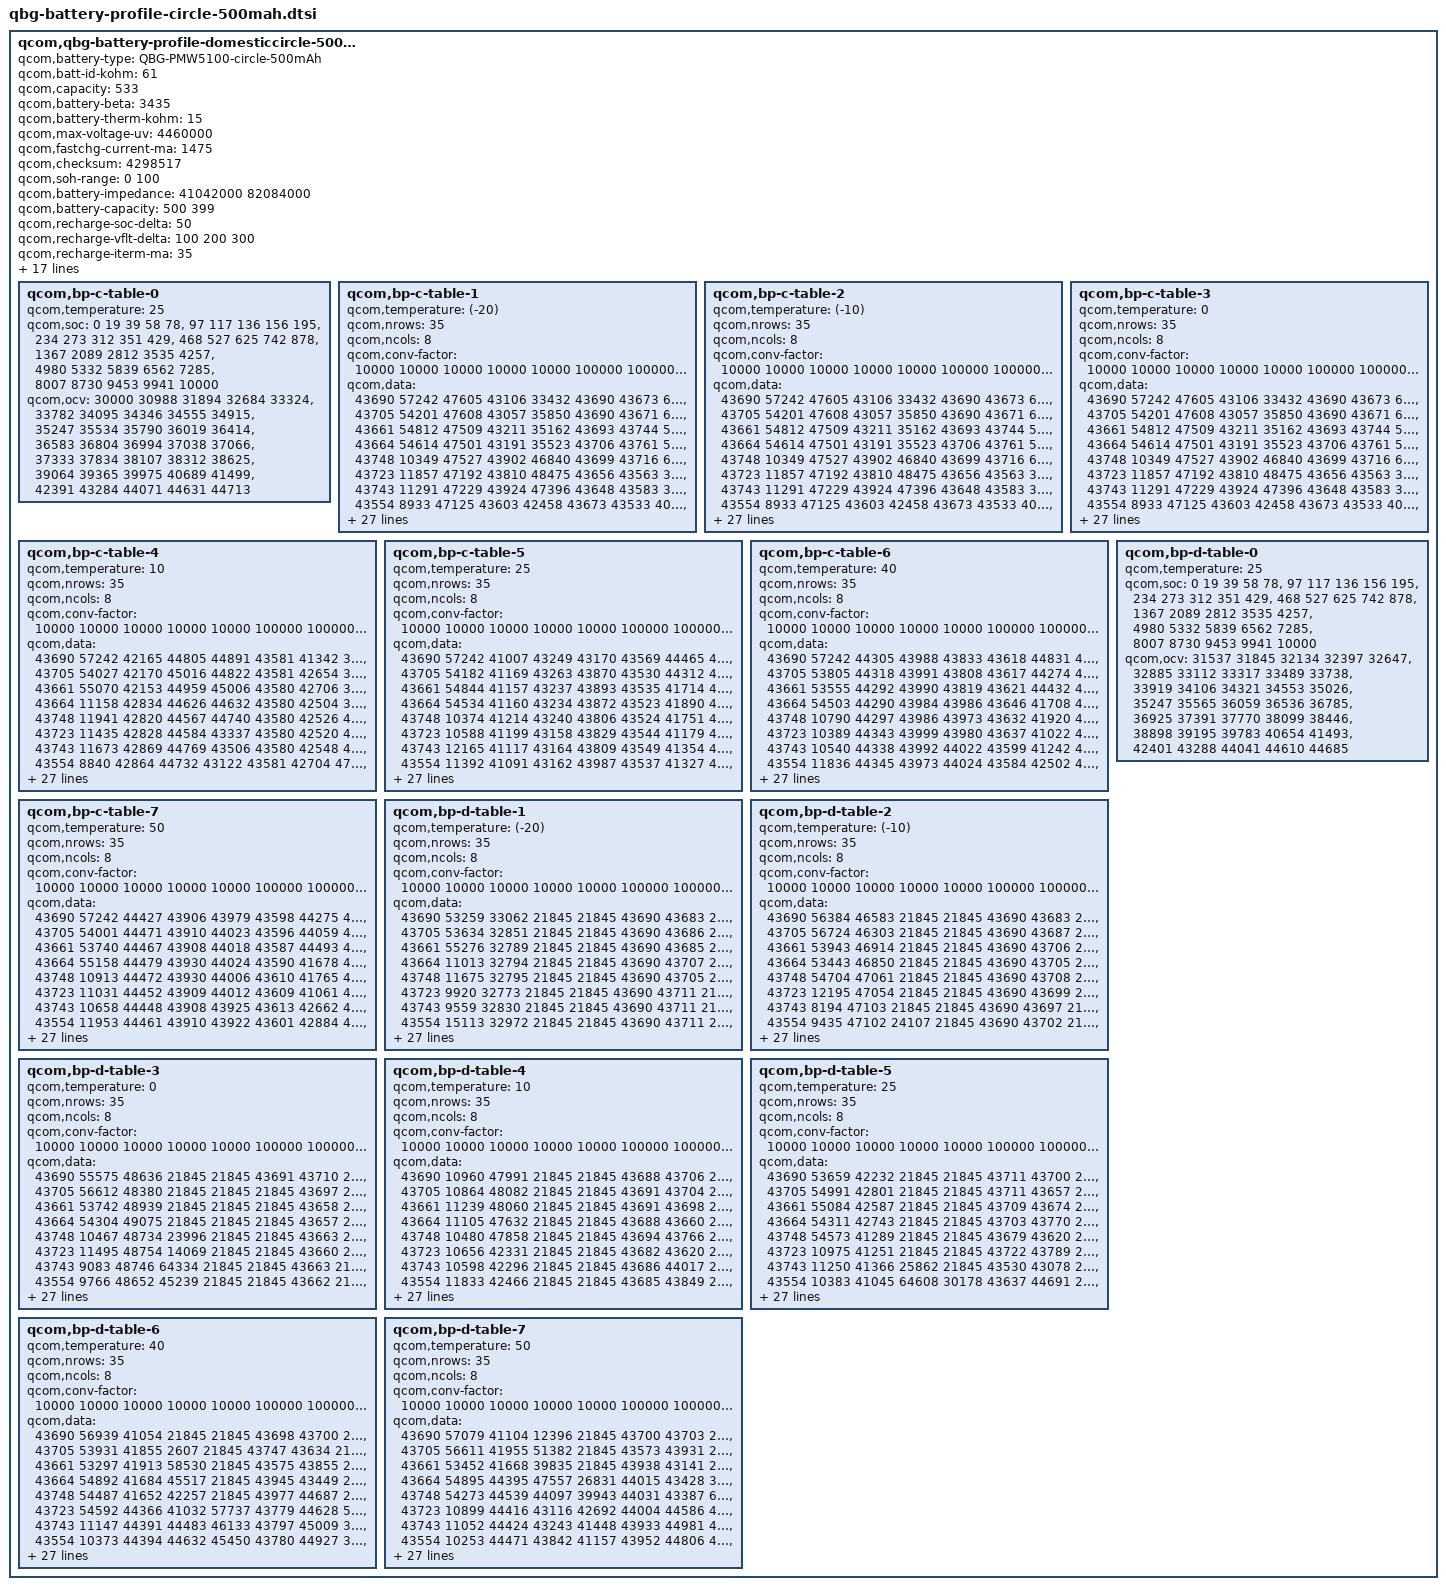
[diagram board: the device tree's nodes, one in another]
qcom,qbg-battery-profile-domesticcircle-500mAh {
	qcom,battery-type = "QBG-PMW5100-circle-500mAh";
	qcom,batt-id-kohm = <61>;
	qcom,capacity = <533>;
	qcom,battery-beta = <3435>;
	qcom,battery-therm-kohm = <15>;
	qcom,max-voltage-uv = <4460000>;
	qcom,fastchg-current-ma = <1475>;
	qcom,checksum = <4298517>; /*@5, 0.005V, 7% */
	qcom,soh-range = <0 100>;
	/* Nominal_Impedance in 10nohm @ SOC 50% 25C* 0:fresh cell,  1: aged cell */
	qcom,battery-impedance = <41042000 82084000>;
	/* Nominal_Capacity in mAh. 0: fresh cell,  1:aged cell */
	qcom,battery-capacity = <500 399>;
	/* SOC delta (in percent) dropped from EOC SOC to enable recharge */
	qcom,recharge-soc-delta =<50>;
	/* vfloat delta (in mV) dropped from regular vfloat in recharge */
	qcom,recharge-vflt-delta =<100 200 300>;
	/* Termination current (in mA) in recharge */
	qcom,recharge-iterm-ma = <35>;
	qcom,batt-temp-coeffs = <0 20 70 170 390 410 420 440 530>;
	qcom,batt-current-coeffs = <0 75000 225000 475000 1475000 1275000 775000 375000 225000>;
	qcom,batt-max-mv-coeffs = <4130000 4460000>;
	qcom,chg-limit-current-default = <100000 150000>;

	qcom,jeita-fcc-ranges = <0 170 475000
				171 440 1475000
				441 530 225000>;

	 qcom,jeita-fv-ranges = <0 170 4460000
				171 440 4460000
				441 530 4130000>;

	qcom,step-chg-ranges = <3400000 4250000 1475000
				4250001 4350000 975000
				4350001 4460000 575000>;

	/* COOL = 15 DegC, WARM = 70 DegC */
	qcom,jeita-soft-thresholds = <0x30DD 0x7BC>;
	/* COLD = 0 DegC, HOT = 80 DegC */
	qcom,jeita-hard-thresholds = <0x3733 0x5ed>;
	/* COOL = 18 DegC, WARM = 39 DegC*/
	qcom,jeita-soft-hys-thresholds = <0x256e 0x161b>;
	qcom,jeita-soft-fcc-ua = <100000 1475000>;
	qcom,jeita-soft-fv-uv = <4130000 4460000>;

	qcom,bp-c-table-0 {
		qcom,temperature = <25>;
		qcom,soc = <    0    19    39    58    78>,
			<   97   117   136   156   195>,
			<  234   273   312   351   429>,
			<  468   527   625   742   878>,
			< 1367  2089  2812  3535  4257>,
			< 4980  5332  5839  6562  7285>,
			< 8007  8730  9453  9941 10000>;
		qcom,ocv = <30000 30988 31894 32684 33324>,
			<33782 34095 34346 34555 34915>,
			<35247 35534 35790 36019 36414>,
			<36583 36804 36994 37038 37066>,
			<37333 37834 38107 38312 38625>,
			<39064 39365 39975 40689 41499>,
			<42391 43284 44071 44631 44713>;
	};

	qcom,bp-c-table-1 {
		qcom,temperature = <(-20)>;
		qcom,nrows = <35>;
		qcom,ncols = <8>;
		qcom,conv-factor = <10000 10000 10000 10000 10000 100000 100000 10000>;
		qcom,data = <43690 57242 47605 43106 33432 43690 43673 63810>,
			<43705 54201 47608 43057 35850 43690 43671 64309>,
			<43661 54812 47509 43211 35162 43693 43744 58558>,
			<43664 54614 47501 43191 35523 43706 43761 58162>,
			<43748 10349 47527 43902 46840 43699 43716 61142>,
			<43723 11857 47192 43810 48475 43656 43563 38334>,
			<43743 11291 47229 43924 47396 43648 43583 37659>,
			<43554  8933 47125 43603 42458 43673 43533 40457>,
			<43574  9059 47104 43543 41335 43665 43548 39573>,
			<43625  9889 47160 43718 44508 43745 43619 32799>,
			<43584 10222 47161 43768 44141 43763 43622 33584>,
			<43963  9355 47152 43758 44241 43727 43617 33726>,
			<43922  9330 47159 43677 44264 43740 43616 33328>,
			<44021  9507 47314 43651 44205 43581 43628 33445>,
			<43783 15092 47249 43699 44925 43621 43624 36332>,
			<43902 14886 47333 43709 44915 43637 43624 36256>,
			<43173 14879 47308 43711 44917 43588 43624 35954>,
			<43227 14960 47115 43697 44890 43633 43622 35856>,
			<43084 15278 47308 43657 44205 43523 43632 35949>,
			<43460 15339 47344 43656 44223 43525 43595 36050>,
			<45053 14384 47328 45051 43098 43522 41439 36250>,
			<41603 16085 47271 44806 44750 43547 42554 36330>,
			<41046 16379 47958 44221 44977 43547 42506 36332>,
			<42853 15525 47946 44286 44929 43524 42645 35940>,
			<47627 15744 47889 44224 45015 43526 41826 35939>,
			<47582 12842 47905 44250 44412 43525 42636 33534>,
			<48766 13178 47919 44281 44093 43524 42542 35952>,
			<48229 14057 48068 44165 43457 43626 41041 35230>,
			<45832 13385 48075 44283 43374 43527 41938 35310>,
			<46815  2930 47700 44038 44691 43534 41546 36492>,
			<46573  3971 47688 44119 44623 43534 44290 36609>,
			<34992   560 48008 44317 44337 43529 44822 33068>,
			<36423   284 48124 44417 48085 43534 43306 37331>,
			<35967  1894 47874 43848 47516 43712 44004 38047>,
			<36282  1208 47977 43671 47959 43760 43632 38457>;
	};

	qcom,bp-c-table-2 {
		qcom,temperature = <(-10)>;
		qcom,nrows = <35>;
		qcom,ncols = <8>;
		qcom,conv-factor = <10000 10000 10000 10000 10000 100000 100000 10000>;
		qcom,data = <43690 57242 47605 43106 33432 43690 43673 63810>,
			<43705 54201 47608 43057 35850 43690 43671 64309>,
			<43661 54812 47509 43211 35162 43693 43744 58558>,
			<43664 54614 47501 43191 35523 43706 43761 58162>,
			<43748 10349 47527 43902 46840 43699 43716 61142>,
			<43723 11857 47192 43810 48475 43656 43563 38334>,
			<43743 11291 47229 43924 47396 43648 43583 37659>,
			<43554  8933 47125 43603 42458 43673 43533 40457>,
			<43574  9059 47104 43543 41335 43665 43548 39573>,
			<43625  9889 47160 43718 44508 43745 43619 32799>,
			<43584 10222 47161 43768 44141 43763 43622 33584>,
			<43963  9355 47152 43758 44241 43727 43617 33726>,
			<43922  9330 47159 43677 44264 43740 43616 33328>,
			<44021  9507 47314 43651 44205 43581 43628 33445>,
			<43783 15092 47249 43699 44925 43621 43624 36332>,
			<43902 14886 47333 43709 44915 43637 43624 36256>,
			<43173 14879 47308 43711 44917 43588 43624 35954>,
			<43227 14960 47115 43697 44890 43633 43622 35856>,
			<43084 15278 47308 43657 44205 43523 43632 35949>,
			<43460 15339 47344 43656 44223 43525 43595 36050>,
			<45053 14384 47328 45051 43098 43522 41439 36250>,
			<41603 16085 47271 44806 44750 43547 42554 36330>,
			<41046 16379 47958 44221 44977 43547 42506 36332>,
			<42853 15525 47946 44286 44929 43524 42645 35940>,
			<47627 15744 47889 44224 45015 43526 41826 35939>,
			<47582 12842 47905 44250 44412 43525 42636 33534>,
			<48766 13178 47919 44281 44093 43524 42542 35952>,
			<48229 14057 48068 44165 43457 43626 41041 35230>,
			<45832 13385 48075 44283 43374 43527 41938 35310>,
			<46815  2930 47700 44038 44691 43534 41546 36492>,
			<46573  3971 47688 44119 44623 43534 44290 36609>,
			<34992   560 48008 44317 44337 43529 44822 33068>,
			<36423   284 48124 44417 48085 43534 43306 37331>,
			<35967  1894 47874 43848 47516 43712 44004 38047>,
			<36282  1208 47977 43671 47959 43760 43632 38457>;
	};

	qcom,bp-c-table-3 {
		qcom,temperature = <0>;
		qcom,nrows = <35>;
		qcom,ncols = <8>;
		qcom,conv-factor = <10000 10000 10000 10000 10000 100000 100000 10000>;
		qcom,data = <43690 57242 47605 43106 33432 43690 43673 63810>,
			<43705 54201 47608 43057 35850 43690 43671 64309>,
			<43661 54812 47509 43211 35162 43693 43744 58558>,
			<43664 54614 47501 43191 35523 43706 43761 58162>,
			<43748 10349 47527 43902 46840 43699 43716 61142>,
			<43723 11857 47192 43810 48475 43656 43563 38334>,
			<43743 11291 47229 43924 47396 43648 43583 37659>,
			<43554  8933 47125 43603 42458 43673 43533 40457>,
			<43574  9059 47104 43543 41335 43665 43548 39573>,
			<43625  9889 47160 43718 44508 43745 43619 32799>,
			<43584 10222 47161 43768 44141 43763 43622 33584>,
			<43963  9355 47152 43758 44241 43727 43617 33726>,
			<43922  9330 47159 43677 44264 43740 43616 33328>,
			<44021  9507 47314 43651 44205 43581 43628 33445>,
			<43783 15092 47249 43699 44925 43621 43624 36332>,
			<43902 14886 47333 43709 44915 43637 43624 36256>,
			<43173 14879 47308 43711 44917 43588 43624 35954>,
			<43227 14960 47115 43697 44890 43633 43622 35856>,
			<43084 15278 47308 43657 44205 43523 43632 35949>,
			<43460 15339 47344 43656 44223 43525 43595 36050>,
			<45053 14384 47328 45051 43098 43522 41439 36250>,
			<41603 16085 47271 44806 44750 43547 42554 36330>,
			<41046 16379 47958 44221 44977 43547 42506 36332>,
			<42853 15525 47946 44286 44929 43524 42645 35940>,
			<47627 15744 47889 44224 45015 43526 41826 35939>,
			<47582 12842 47905 44250 44412 43525 42636 33534>,
			<48766 13178 47919 44281 44093 43524 42542 35952>,
			<48229 14057 48068 44165 43457 43626 41041 35230>,
			<45832 13385 48075 44283 43374 43527 41938 35310>,
			<46815  2930 47700 44038 44691 43534 41546 36492>,
			<46573  3971 47688 44119 44623 43534 44290 36609>,
			<34992   560 48008 44317 44337 43529 44822 33068>,
			<36423   284 48124 44417 48085 43534 43306 37331>,
			<35967  1894 47874 43848 47516 43712 44004 38047>,
			<36282  1208 47977 43671 47959 43760 43632 38457>;
	};

	qcom,bp-c-table-4 {
		qcom,temperature = <10>;
		qcom,nrows = <35>;
		qcom,ncols = <8>;
		qcom,conv-factor = <10000 10000 10000 10000 10000 100000 100000 10000>;
		qcom,data = <43690 57242 42165 44805 44891 43581 41342 35171>,
			<43705 54027 42170 45016 44822 43581 42654 34932>,
			<43661 55070 42153 44959 45006 43580 42706 35663>,
			<43664 11158 42834 44626 44632 43580 42504 35401>,
			<43748 11941 42820 44567 44740 43580 42526 46410>,
			<43723 11435 42828 44584 43337 43580 42520 46155>,
			<43743 11673 42869 44769 43506 43580 42548 46916>,
			<43554  8840 42864 44732 43122 43581 42704 47015>,
			<43574  8776 42879 43342 43200 43581 42720 46831>,
			<43625  8335 42855 43301 43847 43571 41319 45490>,
			<43584  8702 42849 43502 43903 43574 41093 45259>,
			<43963  9981 42855 43438 43885 43573 44296 45940>,
			<43922 10134 42851 43085 43882 43529 44045 45864>,
			<44021  9377 42783 43135 43792 43523 44078 46056>,
			<43783  9672 42810 43117 43782 43525 44059 45694>,
			<43902  9560 42963 43115 43838 43546 44468 45620>,
			<43173 15094 42974 43028 43823 43544 44524 45793>,
			<43227 14901 42964 43118 43973 43550 44505 48477>,
			<43084 14955 42968 43133 43823 43548 41647 48465>,
			<43460 14918 42960 43087 43804 43548 41626 45753>,
			<45053 14469 42944 43487 43222 43624 41412 45594>,
			<41603 16049 42977 43294 43271 43617 42626 45965>,
			<41046 16288 42943 43350 44683 43616 42560 45981>,
			<42853 16225 42921 44674 44708 43631 42584 45682>,
			<47627 15452 42621 44760 43353 43541 41048 45581>,
			<47582 12811 42503 44692 45027 43624 44048 46029>,
			<48766 13175 42532 44790 44989 43618 42936 45963>,
			<48229 13955 42704 44712 43445 43624 41448 48169>,
			<45832 13405 42740 44710 43073 43541 41969 48264>,
			<46815  2215 42646 44776 43416 43540 41691 48134>,
			<46573  4048 42641 44736 43284 43540 44529 48413>,
			<34992   595 42734 44622 44565 43541 44145 45898>,
			<36423  1697 42713 44975 41172 43618 44796 34994>,
			<35967  1179 42561 43039 42352 43572 43888 36196>,
			<36282  1241 42558 43167 41247 43581 43812 35119>;
	};

	qcom,bp-c-table-5 {
		qcom,temperature = <25>;
		qcom,nrows = <35>;
		qcom,ncols = <8>;
		qcom,conv-factor = <10000 10000 10000 10000 10000 100000 100000 10000>;
		qcom,data = <43690 57242 41007 43249 43170 43569 44465 47288>,
			<43705 54182 41169 43263 43870 43530 44312 47993>,
			<43661 54844 41157 43237 43893 43535 41714 47929>,
			<43664 54534 41160 43234 43872 43523 41890 48126>,
			<43748 10374 41214 43240 43806 43524 41751 48063>,
			<43723 10588 41199 43158 43829 43544 41179 47731>,
			<43743 12165 41117 43164 43809 43549 41354 47626>,
			<43554 11392 41091 43162 43987 43537 41327 47809>,
			<43574 11345 41142 43137 43971 43540 42737 47766>,
			<43625  8905 41132 43145 44027 43631 42984 42309>,
			<43584  8965 41816 43190 44008 43619 42836 42259>,
			<43963  8292 41802 43196 43933 43623 42021 42277>,
			<43922  8548 41840 43173 43928 43643 42030 42439>,
			<44021  9753 41843 43180 43909 43644 42849 42488>,
			<43783  9364 41855 43868 43909 43638 42553 42379>,
			<43902  9293 41850 43844 43930 43636 42679 42400>,
			<43173  9582 41837 43881 43930 43592 41184 42086>,
			<43227 14888 41746 43838 43915 43586 41565 42182>,
			<43084 14852 41730 43800 43915 43598 41241 42202>,
			<43460 14944 41784 43795 44022 43599 41161 42037>,
			<45053 15231 41766 43866 43136 43599 41911 42492>,
			<41603 14688 41973 43184 43075 43589 40980 42356>,
			<41046 15985 41880 43155 43100 43596 42602 42259>,
			<42853 16130 41915 43202 43109 43637 42738 42452>,
			<47627 15435 41543 43071 43110 43638 41537 42459>,
			<47582 12850 41490 43013 43296 43592 44065 47788>,
			<48766 13167 41484 43049 43352 43586 44461 47755>,
			<48229 13965 41511 43147 43177 43643 41777 42760>,
			<45832 13403 41718 43189 43842 43644 44370 42992>,
			<46815  2225 41620 43242 43165 43644 44418 42754>,
			<46573  3901 41604 43203 43037 43644 44089 42233>,
			<34992   958 41631 43024 43469 43598 44057 42274>,
			<36423  1677 41677 43091 44204 43611 44833 47547>,
			<35967  1277 41498 43146 41707 43616 43453 49026>,
			<36282  1027 41517 43776 41473 43635 43185 49030>;
	};

	qcom,bp-c-table-6 {
		qcom,temperature = <40>;
		qcom,nrows = <35>;
		qcom,ncols = <8>;
		qcom,conv-factor = <10000 10000 10000 10000 10000 100000 100000 10000>;
		qcom,data = <43690 57242 44305 43988 43833 43618 44831 41266>,
			<43705 53805 44318 43991 43808 43617 44274 41257>,
			<43661 53555 44292 43990 43819 43621 44432 41413>,
			<43664 54503 44290 43984 43986 43646 41708 41457>,
			<43748 10790 44297 43986 43973 43632 41920 41452>,
			<43723 10389 44343 43999 43980 43637 41022 41368>,
			<43743 10540 44338 43992 44022 43599 41242 41396>,
			<43554 11836 44345 43973 44024 43584 42502 41376>,
			<43574 12245 44324 43974 44003 43588 42974 41052>,
			<43625 11710 44332 43983 43935 43608 42120 41061>,
			<43584  8919 44330 44016 43956 43609 42818 40969>,
			<43963  8985 44497 44026 43939 43614 42802 41174>,
			<43922  8303 44509 44005 43604 43612 42869 41155>,
			<44021  8466 44510 44024 43612 43606 42387 41205>,
			<43783 10224 44485 44005 43589 43945 42271 41187>,
			<43902  9381 44486 44000 43590 43948 42466 41110>,
			<43173  9647 44495 44012 43598 43936 42454 41091>,
			<43227 15037 44535 43956 43622 43954 42816 41842>,
			<43084 15045 44531 43951 43625 43913 42938 41733>,
			<43460 14883 44537 43936 43606 43957 41978 41796>,
			<45053 15297 44525 44012 43975 43964 41197 40998>,
			<41603 14832 44440 44025 43889 43957 41387 41029>,
			<41046 15934 44470 43921 43828 43963 41248 41000>,
			<42853 16343 44115 44017 43839 43944 41096 41000>,
			<47627 15468 44149 43820 43900 43613 44437 41076>,
			<47582 12835 44137 43886 43152 43612 44085 41422>,
			<48766 13165 44063 43833 43256 43605 44212 41454>,
			<48229 14002 44085 43929 43934 43939 41762 41776>,
			<45832 13388 44245 43921 43910 43936 41479 41942>,
			<46815  2237 44235 43980 43985 43947 41688 41840>,
			<46573  3903 44260 43823 43852 43944 44337 41213>,
			<34992   932 44256 43828 43208 43950 44096 41055>,
			<36423  1716 44235 43871 43485 43604 44092 42535>,
			<35967  1223 44073 43878 44594 43639 44580 42757>,
			<36282  1133 44228 43967 44954 43915 43236 42790>;
	};

	qcom,bp-c-table-7 {
		qcom,temperature = <50>;
		qcom,nrows = <35>;
		qcom,ncols = <8>;
		qcom,conv-factor = <10000 10000 10000 10000 10000 100000 100000 10000>;
		qcom,data = <43690 57242 44427 43906 43979 43598 44275 41186>,
			<43705 54001 44471 43910 44023 43596 44059 41109>,
			<43661 53740 44467 43908 44018 43587 44493 41116>,
			<43664 55158 44479 43930 44024 43590 41678 41094>,
			<43748 10913 44472 43930 44006 43610 41765 41096>,
			<43723 11031 44452 43909 44012 43609 41061 41148>,
			<43743 10658 44448 43908 43925 43613 42662 41120>,
			<43554 11953 44461 43910 43922 43601 42884 41814>,
			<43574 12205 44462 43904 43931 43604 42166 41797>,
			<43625 11317 44117 43918 43915 43945 42071 41851>,
			<43584  8865 44113 43952 43940 43938 42061 41734>,
			<43963  9198 44125 43940 43601 43942 42082 41773>,
			<43922  8434 44127 43937 43610 43940 42079 41950>,
			<44021  8676 44121 43936 43587 43941 42319 41923>,
			<43783  9817 44101 43939 43638 43966 48026 41977>,
			<43902  9986 44103 43938 43647 43955 47978 41955>,
			<43173  9269 44096 43938 43622 43958 47218 41873>,
			<43227  9581 44108 43610 43521 43930 47112 41564>,
			<43084 15001 44105 43619 43581 44010 42177 41488>,
			<43460 15078 44107 43595 43626 43932 41373 41552>,
			<45053 15241 44145 43938 43919 43921 41238 41775>,
			<41603 14776 44154 43949 43983 44015 41032 41757>,
			<41046 16067 44138 43614 43909 43921 42707 41972>,
			<42853 16322 44033 43965 43928 43918 41353 41936>,
			<47627 15382 44095 44011 43993 43960 41698 41846>,
			<47582 12838 44245 44016 43799 43941 44087 41089>,
			<48766 13158 44251 44027 43880 43953 44114 41137>,
			<48229 14005 44278 43598 43599 43909 41167 41472>,
			<45832 13389 44183 43609 43613 43931 41837 41498>,
			<46815  2224 44170 43957 44009 43917 41813 41888>,
			<46573  3890 44885 43931 43824 43914 41681 41969>,
			<34992   937 44890 44029 43871 43956 41477 41829>,
			<36423  1720 44868 43991 43255 43954 44412 41153>,
			<35967  1220 44203 43999 43483 43605 44835 41278>,
			<36282  1127 44879 43949 44581 43935 43061 42624>;
	};

	qcom,bp-d-table-0 {
		qcom,temperature = <25>;
		qcom,soc = <    0    19    39    58    78>,
			<   97   117   136   156   195>,
			<  234   273   312   351   429>,
			<  468   527   625   742   878>,
			< 1367  2089  2812  3535  4257>,
			< 4980  5332  5839  6562  7285>,
			< 8007  8730  9453  9941 10000>;
		qcom,ocv = <31537 31845 32134 32397 32647>,
			<32885 33112 33317 33489 33738>,
			<33919 34106 34321 34553 35026>,
			<35247 35565 36059 36536 36785>,
			<36925 37391 37770 38099 38446>,
			<38898 39195 39783 40654 41493>,
			<42401 43288 44041 44610 44685>;
	};

	qcom,bp-d-table-1 {
		qcom,temperature = <(-20)>;
		qcom,nrows = <35>;
		qcom,ncols = <8>;
		qcom,conv-factor = <10000 10000 10000 10000 10000 100000 100000 10000>;
		qcom,data = <43690 53259 33062 21845 21845 43690 43683 21845>,
			<43705 53634 32851 21845 21845 43690 43686 21845>,
			<43661 55276 32789 21845 21845 43690 43685 21845>,
			<43664 11013 32794 21845 21845 43690 43707 21845>,
			<43748 11675 32795 21845 21845 43690 43705 21845>,
			<43723  9920 32773 21845 21845 43690 43711 21845>,
			<43743  9559 32830 21845 21845 43690 43711 21845>,
			<43554 15113 32972 21845 21845 43690 43711 21845>,
			<43574 14434 32899 21845 21845 43690 43711 21845>,
			<43625 16116 33585 21845 21845 43690 43710 21845>,
			<43584 15874 33666 21845 21845 43690 43710 21845>,
			<43963 14634 33284 21845 21845 43690 43705 21845>,
			<43922 15181 33524 21845 21845 43690 43707 21845>,
			<44021 15339 33507 21845 21845 43690 43707 21845>,
			<43783 14915 36171 21845 21845 43690 43704 21845>,
			<43902 15271 36314 21845 21845 43690 43710 21845>,
			<43173 15260 35892 21845 21845 43690 43698 21845>,
			<43227 15051 36058 21845 26775 43694 44698 21845>,
			<43084  9540 36675 21845 42189 43693 44882 21845>,
			<43460 15098 36018 21845 47823 43682 44991 21845>,
			<45053 15241 35166  6256 42109 43680 44699 21845>,
			<41603 14468 36562 12193 47790 43688 43146 21845>,
			<41046 14847 35144 50069 42104 43688 43157 21845>,
			<42853 16121 36600 65310 42170 43688 43162 24435>,
			<47627 16367 35080 60544 42956 43688 43180 18559>,
			<47582 15564 35134 37660 42799 43688 43849 32347>,
			<48766 15757 35176 40466 42790 43688 43167 25661>,
			<48229 12887 35153 39329 48010 43688 44554 25877>,
			<45832 14054 36526 39606 45406 43688 44784 32554>,
			<46815 13636 35124 39459 36787 43689 43369 30311>,
			<46573  2448 35100 39151 35906 43689 43128 30075>,
			<34992  3184 35252 39958 33582 43689 43069 19752>,
			<36423    25 35242 38213 36612 43689 43842 17461>,
			<35967  1259 35075 57345 45085 43689 43809 23067>,
			<36282  1044 35172 57725 46068 43689 43819 23061>;
	};

	qcom,bp-d-table-2 {
		qcom,temperature = <(-10)>;
		qcom,nrows = <35>;
		qcom,ncols = <8>;
		qcom,conv-factor = <10000 10000 10000 10000 10000 100000 100000 10000>;
		qcom,data = <43690 56384 46583 21845 21845 43690 43683 21845>,
			<43705 56724 46303 21845 21845 43690 43687 21845>,
			<43661 53943 46914 21845 21845 43690 43706 21845>,
			<43664 53443 46850 21845 21845 43690 43705 21845>,
			<43748 54704 47061 21845 21845 43690 43708 21845>,
			<43723 12195 47054 21845 21845 43690 43699 21845>,
			<43743  8194 47103 21845 21845 43690 43697 21845>,
			<43554  9435 47102 24107 21845 43690 43702 21845>,
			<43574 15036 47043 32392 21845 43690 43702 21845>,
			<43625 15208 46860 30130 21845 43690 43696 21845>,
			<43584 14541 46955 18074 21845 43690 43699 21845>,
			<43963 15110 46896 30400 21845 43690 43698 21845>,
			<43922 15045 47097  7469 21845 43690 43709 21845>,
			<44021 15029 47031 13980 21845 43690 43698 21845>,
			<43783 14956 46722 11086 21845 43691 43701 21845>,
			<43902 15056 45433 14193 17855 43689 47585 21845>,
			<43173  9631 45351 21845 47463 43680 58120 21845>,
			<43227  9677 45499 31405 44147 43683 42499 21845>,
			<43084  9480 45137  5040 41736 43695 44591 21845>,
			<43460  9571 45058 13660 41214 43689 43040 21845>,
			<45053 14948 45068 52667 41440 43688 43203 20128>,
			<41603 14532 45146 38822 41279 43688 43123  7766>,
			<41046 14632 45150 36598 41108 43689 43057 16374>,
			<42853 16118 45443 48220 41869 43689 43209 11163>,
			<47627 16366 45143 42465 41477 43694 43162 55360>,
			<47582 15477 45114 42857 41151 43692 43289 50930>,
			<48766 12980 45269 42045 42895 43682 44573 51072>,
			<48229 12436 45265 42151 47287 43665 44955 55925>,
			<45832 13490 45111 47792 45394 43557 44882 54799>,
			<46815  3043 45266 47339 46744 43734 44751 55134>,
			<46573  3645 45290 48800 45263 43719 44749 54688>,
			<34992   674 45297 48757 45478 43727 44700 10553>,
			<36423   433 45097 48242 48550 43709 43249 10310>,
			<35967  1261 45114 46030 47965 43690 43674 55229>,
			<36282  1044 45113 45874 47881 43690 43690 54947>;
	};

	qcom,bp-d-table-3 {
		qcom,temperature = <0>;
		qcom,nrows = <35>;
		qcom,ncols = <8>;
		qcom,conv-factor = <10000 10000 10000 10000 10000 100000 100000 10000>;
		qcom,data = <43690 55575 48636 21845 21845 43691 43710 21845>,
			<43705 56612 48380 21845 21845 21845 43697 21845>,
			<43661 53742 48939 21845 21845 21845 43658 21845>,
			<43664 54304 49075 21845 21845 21845 43657 21845>,
			<43748 10467 48734 23996 21845 21845 43663 21845>,
			<43723 11495 48754 14069 21845 21845 43660 21845>,
			<43743  9083 48746 64334 21845 21845 43663 21845>,
			<43554  9766 48652 45239 21845 21845 43662 21845>,
			<43574 10018 48675 44107 21845 21845 43656 21845>,
			<43625 10155 48869 45761 21845 47293 43700 21845>,
			<43584  9778 48819 65092 21845 43692 34331 21845>,
			<43963  9784 47477  7246 21845 43693 11676 21845>,
			<43922  9756 47385 20708 59069 43686 13380 21845>,
			<44021 10113 47396 22398 41671 43686 65208 21845>,
			<43783  9466 47592  5779 42954 43695 44581 21845>,
			<43902  9265 47505  3875 42790 43689 43393 21845>,
			<43173  9331 47595 10774 42556 43688 43045 19747>,
			<43227  9609 47539 64241 41155 43688 43068  5742>,
			<43084  9718 47551 40729 41503 43688 43064 12550>,
			<43460  9535 47540 36803 44312 43688 43011 12131>,
			<45053 14956 47230 48023 44393 43694 43099 53233>,
			<41603 14395 47228 41651 44400 43680 43458 57821>,
			<41046 14643 47127 44862 44893 43665 44796 38868>,
			<42853 16112 47182 44703 44570 43718 43473 40544>,
			<47627 16156 47182 45001 45021 43530 44335 38913>,
			<47582 15666 47221 44927 44505 43532 44138 39146>,
			<48766 12903 47223 44182 41909 43522 44048 39363>,
			<48229 12726 47105 44495 42081 43544 44243 37838>,
			<45832 13348 47308 41535 47509 43520 44689 37906>,
			<46815  2825 47311 41766 42025 43583 44711 38570>,
			<46573  4031 47242 41783 42836 43556 44660 38495>,
			<34992   559 47260 41932 42410 43576 44970 60144>,
			<36423   297 47274 41587 41305 43556 44575 59922>,
			<35967  1273 47118 41618 44405 43567 44593 38810>,
			<36282  1040 47202 41615 44387 43566 44595 38604>;
	};

	qcom,bp-d-table-4 {
		qcom,temperature = <10>;
		qcom,nrows = <35>;
		qcom,ncols = <8>;
		qcom,conv-factor = <10000 10000 10000 10000 10000 100000 100000 10000>;
		qcom,data = <43690 10960 47991 21845 21845 43688 43706 21845>,
			<43705 10864 48082 21845 21845 43691 43704 21845>,
			<43661 11239 48060 21845 21845 43691 43698 21845>,
			<43664 11105 47632 21845 21845 43688 43660 21845>,
			<43748 10480 47858 21845 21845 43694 43766 21845>,
			<43723 10656 42331 21845 21845 43682 43620 21845>,
			<43743 10598 42296 21845 21845 43686 44017 21845>,
			<43554 11833 42466 21845 21845 43685 43849 21845>,
			<43574 12281 42418 21845 50825 43706 43239 21845>,
			<43625 11371 42107 21845 40012 43684 43087 21845>,
			<43584  8882 42033 17148 46363 43680 43494 21845>,
			<43963  9118 42203 16052 45605 43692 43466 23218>,
			<43922  8332 42213 50002 48763 43689 43508 31431>,
			<44021  8617 42216 57621 47346 43691 43464  7996>,
			<43783  9791 42236 34852 42054 43688 43268 10831>,
			<43902 10219 42179 45220 42853 43689 43375 56315>,
			<43173  9396 42023 47177 42541 43695 43390 52180>,
			<43227  9298 42209 42514 41137 43683 43364 58753>,
			<43084  9675 42238 41678 44499 43711 43363 59906>,
			<43460  9486 42237 44185 44890 43651 44743 39974>,
			<45053 14896 42142 44766 44972 43765 44217 32963>,
			<41603 14548 42823 43476 44678 43528 44424 35412>,
			<41046 14653 42780 43464 44707 43538 41634 46963>,
			<42853 15931 42859 43466 44683 43624 44338 46825>,
			<47627 16199 42797 43324 44687 43631 44294 45443>,
			<47582 15722 42796 43389 44554 43541 44355 45451>,
			<48766 12891 42969 44707 44864 43540 44328 46822>,
			<48229 12769 42987 44567 41460 43625 44921 35056>,
			<45832 13354 42909 45037 41174 43551 43482 34999>,
			<46815  2844 42881 44841 44518 43534 44785 46356>,
			<46573  3995 42898 45028 44456 43534 44947 35463>,
			<34992   515 42901 44956 44355 43527 44910 35039>,
			<36423   271 42906 44618 44523 43551 44890 35289>,
			<35967  1254 42988 44584 45004 43548 44891 35257>,
			<36282  1025 42977 44765 44955 43548 44869 34910>;
	};

	qcom,bp-d-table-5 {
		qcom,temperature = <25>;
		qcom,nrows = <35>;
		qcom,ncols = <8>;
		qcom,conv-factor = <10000 10000 10000 10000 10000 100000 100000 10000>;
		qcom,data = <43690 53659 42232 21845 21845 43711 43700 21845>,
			<43705 54991 42801 21845 21845 43711 43657 21845>,
			<43661 55084 42587 21845 21845 43709 43674 21845>,
			<43664 54311 42743 21845 21845 43703 43770 21845>,
			<43748 54573 41289 21845 21845 43679 43620 21845>,
			<43723 10975 41251 21845 21845 43722 43789 21845>,
			<43743 11250 41366 25862 21845 43530 43078 21845>,
			<43554 10383 41045 64608 30178 43637 44691 21845>,
			<43574 10363 41086 32894 55178 43937 44958  5194>,
			<43625 10592 41020 47683 60648 43931 44166 49374>,
			<43584 11989 41158 41969 40265 43927 44080 63687>,
			<43963 12176 41201 44186 34436 43908 44103 59523>,
			<43922 11451 41213 44616 35589 43602 44438 40820>,
			<44021 11347 41214 44700 45212 43620 44502 34596>,
			<43783  8824 41199 43476 47621 43548 44343 34941>,
			<43902  8965 41107 43420 42908 43544 44335 46195>,
			<43173  8263 41100 43080 41771 43547 44531 45267>,
			<43227  9841 41809 43017 44042 43549 44330 48197>,
			<43084  9234 41797 43062 45021 43625 44460 49136>,
			<43460  9499 41843 43052 44767 43619 44078 47477>,
			<45053 14999 41836 43884 43849 43646 44340 42318>,
			<41603 14501 41791 43800 43844 43584 44503 42377>,
			<41046 14624 41946 43851 43514 43598 44382 47848>,
			<42853 15993 41961 43861 43279 43590 44147 47843>,
			<47627 15492 41905 43169 43030 43645 44517 42405>,
			<47582 15704 41553 43174 43226 43635 44313 42047>,
			<48766 13233 41560 43161 43095 43634 44396 42372>,
			<48229 12749 41592 43024 44266 43637 44168 47184>,
			<45832 13412 41579 43083 44996 43618 43297 47335>,
			<46815  2239 41481 43063 43478 43543 43351 47776>,
			<46573  3851 41472 43065 43105 43626 45044 42457>,
			<34992   946 41490 43230 43134 43626 44262 42291>,
			<36423  1699 41591 43241 43423 43622 44234 47850>,
			<35967  1256 41559 43148 43265 43640 44923 47711>,
			<36282  1063 41898 43144 43282 43640 44824 48033>;
	};

	qcom,bp-d-table-6 {
		qcom,temperature = <40>;
		qcom,nrows = <35>;
		qcom,ncols = <8>;
		qcom,conv-factor = <10000 10000 10000 10000 10000 100000 100000 10000>;
		qcom,data = <43690 56939 41054 21845 21845 43698 43700 21845>,
			<43705 53931 41855  2607 21845 43747 43634 21845>,
			<43661 53297 41913 58530 21845 43575 43855 21845>,
			<43664 54892 41684 45517 21845 43945 43449 21845>,
			<43748 54487 41652 42257 21845 43977 44687 21845>,
			<43723 54592 44366 41032 57737 43779 44628 51742>,
			<43743 11147 44391 44483 46133 43797 45009 34245>,
			<43554 10373 44394 44632 45450 43780 44927 33673>,
			<43574 10635 44317 43463 45686 43823 44212 36742>,
			<43625 11872 44290 43158 48278 43959 44081 35712>,
			<43584 11422 44337 43903 48772 43595 44478 46115>,
			<43963 11764 44347 43784 47292 43623 44323 46768>,
			<43922  8956 44321 43810 42411 43620 44355 45682>,
			<44021  9114 44322 43987 41248 43640 41627 49144>,
			<43783  8293 44331 43971 44145 43638 41680 47656>,
			<43902  8510 44497 43982 45001 43592 41531 42067>,
			<43173  9728 44507 44020 43333 43584 41580 42949>,
			<43227  9452 44482 44028 43229 43615 41571 41289>,
			<43084  9684 44493 43968 43160 43603 44534 41242>,
			<43460  9585 44494 44002 43805 43949 44110 41377>,
			<45053 14996 44517 43941 43960 43964 41445 41120>,
			<41603 14503 44432 43949 43977 43912 41694 41112>,
			<41046 14626 44465 43941 43178 43906 44520 40988>,
			<42853 15949 44118 43942 43047 43904 44837 41352>,
			<47627 15515 44106 43958 43792 43966 44427 41196>,
			<47582 15688 44129 43918 43834 43942 41627 41145>,
			<48766 13246 44139 44018 43200 43942 41635 41399>,
			<48229 12796 44062 43804 43356 43950 44819 42919>,
			<45832 13516 44047 43989 43035 43584 43347 41248>,
			<46815  2870 44091 43984 43873 43587 45003 40992>,
			<46573  4016 44068 43976 43972 43610 44057 41133>,
			<34992   575 44064 44002 44021 43600 44315 41853>,
			<36423   259 44094 43917 43788 43948 44447 41129>,
			<35967  1200 44041 43964 43863 43938 45015 41190>,
			<36282  1220 44047 43964 43182 43938 44945 41209>;
	};

	qcom,bp-d-table-7 {
		qcom,temperature = <50>;
		qcom,nrows = <35>;
		qcom,ncols = <8>;
		qcom,conv-factor = <10000 10000 10000 10000 10000 100000 100000 10000>;
		qcom,data = <43690 57079 41104 12396 21845 43700 43703 21845>,
			<43705 56611 41955 51382 21845 43573 43931 21845>,
			<43661 53452 41668 39835 21845 43938 43141 21845>,
			<43664 54895 44395 47557 26831 44015 43428 30195>,
			<43748 54273 44539 44097 39943 44031 43387 60580>,
			<43723 10899 44416 43116 42692 44004 44586 48616>,
			<43743 11052 44424 43243 41448 43933 44981 49119>,
			<43554 10253 44471 43842 41157 43952 44806 48797>,
			<43574 10508 44467 43800 41841 43945 44174 47563>,
			<43625 12276 44473 43999 41859 43589 44145 47349>,
			<43584 11365 44454 44027 41594 43591 44532 47987>,
			<43963  8866 44460 43923 41509 43590 44393 48095>,
			<43922  9151 44457 43917 41605 43591 41654 47708>,
			<44021  9047 44458 43952 44491 43611 41716 47800>,
			<43783  8493 44112 43963 44557 43601 41485 42984>,
			<43902  9872 44114 43940 43319 43946 41570 42651>,
			<43173 10131 44124 43938 43042 43936 41552 41376>,
			<43227  9218 44120 43966 43172 43941 41570 41012>,
			<43084  9681 44121 43915 43865 43941 41647 40997>,
			<43460  9500 44103 43958 44005 43956 41133 41847>,
			<45053 15000 44107 43615 43947 44008 42204 41976>,
			<41603 15174 44133 43632 43919 44001 41757 41954>,
			<41046 14813 44054 43640 43781 44026 44520 41752>,
			<42853 15989 44041 43644 43870 44002 44907 41819>,
			<47627 15503 44094 43639 44023 44015 44351 41955>,
			<47582 15739 44247 43595 43924 44009 41490 41870>,
			<48766 13219 44254 43963 43151 43908 44379 41105>,
			<48229 12694 44224 43972 43076 43961 44869 41465>,
			<45832 13443 44280 44009 43894 43951 45054 41148>,
			<46815  3046 44189 43931 44007 43948 44528 41976>,
			<46573  3603 44160 43959 43962 43941 41963 41562>,
			<34992   666 44208 43605 43937 43967 41840 41496>,
			<36423   505 44195 43599 43932 43929 41714 41498>,
			<35967  1870 44884 43633 43975 44029 44233 41539>,
			<36282  1175 44887 43632 43995 44016 44176 41567>;
	};

};
